# ATSAMHA1G16AB device description
Architecture: CORTEX-M0PLUS; Family: SAMH; Series: SAMHA1
Registers are 32-bit, read-write, reset 0x0 unless marked. A register's access mark holds for its fields unless they carry their own. Offsets are from the block's base; [hi:lo] are bit positions; lines under a group give offsets from that group; {n}, {i} and the like mark numbered series; 'fields as' and 'values as' point back to an identical list; <NAME> marks a mode.

## RTC — Real-Time Counter
Instances: RTC 0x40001400
Modes: MODE0 when RTC.MODE0.CTRL.MODE=0 (32-bit Counter with Single 32-bit Compare); MODE1 when RTC.MODE1.CTRL.MODE=1 (16-bit Counter with Two 16-bit Compares); MODE2 when RTC.MODE2.CTRL.MODE=2 (Clock/Calendar with Alarm)
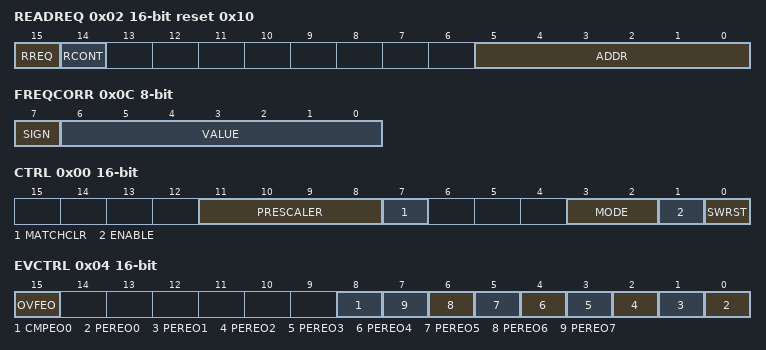
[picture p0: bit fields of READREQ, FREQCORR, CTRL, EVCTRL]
0x02 READREQ 16-bit reset 0x10 — Read Request
  [15] RREQ — Read Request
  [14] RCONT — Read Continuously
  [5:0] ADDR — Address
0x0A STATUS 8-bit
  [7] SYNCBUSY — Synchronization Busy
0x0B DBGCTRL 8-bit — Debug Control
  [0] DBGRUN — Run During Debug
0x0C FREQCORR 8-bit (WSYNC) — Frequency Correction
  [7] SIGN — Correction Sign
  [6:0] VALUE — Correction Value
0x00 CTRL <MODE0> 16-bit (WSYNC) — MODE0 Control
  [11:8] PRESCALER
    0=DIV1 (CLK_RTC_CNT = GCLK_RTC/1); 1=DIV2 (CLK_RTC_CNT = GCLK_RTC/2); 2=DIV4 (CLK_RTC_CNT = GCLK_RTC/4); 3=DIV8 (CLK_RTC_CNT = GCLK_RTC/8); 4=DIV16 (CLK_RTC_CNT = GCLK_RTC/16); 5=DIV32 (CLK_RTC_CNT = GCLK_RTC/32); 6=DIV64 (CLK_RTC_CNT = GCLK_RTC/64); 7=DIV128 (CLK_RTC_CNT = GCLK_RTC/128); 8=DIV256 (CLK_RTC_CNT = GCLK_RTC/256); 9=DIV512 (CLK_RTC_CNT = GCLK_RTC/512); 10=DIV1024 (CLK_RTC_CNT = GCLK_RTC/1024)
  [7] MATCHCLR — Clear on Match
  [3:2] MODE — Operating Mode
    0=COUNT32 (Mode 0: 32-bit Counter); 1=COUNT16 (Mode 1: 16-bit Counter); 2=CLOCK (Mode 2: Clock/Calendar)
  [1] ENABLE
  [0] SWRST — Software Reset
0x04 EVCTRL <MODE0> 16-bit — MODE0 Event Control
  [15] OVFEO — Overflow Event Output Enable
  [8] CMPEO0 — Compare 0 Event Output Enable
  [n] PEREO{n} (n=0..7) — Periodic Interval {n} Event Output Enable
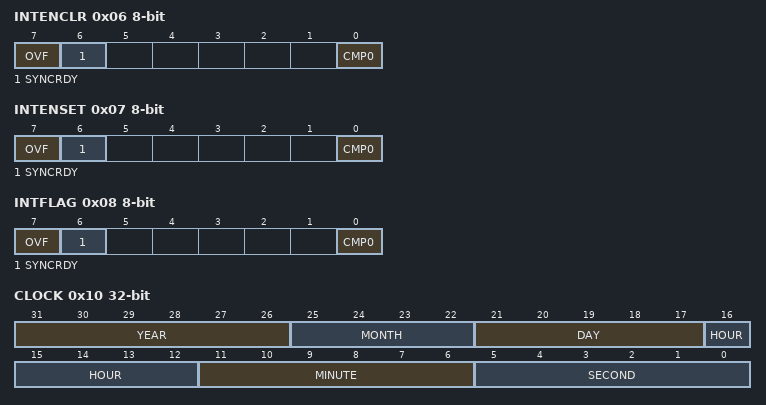
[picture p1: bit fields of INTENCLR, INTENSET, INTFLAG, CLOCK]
0x06 INTENCLR <MODE0> 8-bit (atomic clear) — MODE0 Interrupt Enable Clear
  [7] OVF — Overflow Interrupt Enable
  [6] SYNCRDY — Synchronization Ready Interrupt Enable
  [0] CMP0 — Compare 0 Interrupt Enable
0x07 INTENSET <MODE0> 8-bit (atomic set) — MODE0 Interrupt Enable Set
  fields as INTENCLR<MODE0>
0x08 INTFLAG <MODE0> 8-bit (atomic clear) — MODE0 Interrupt Flag Status and Clear
  [7] OVF — Overflow
  [6] SYNCRDY — Synchronization Ready
  [0] CMP0 — Compare 0
0x10 COUNT <MODE0> (RWSYNC) — MODE0 Counter Value
  [31:0] COUNT — Counter Value
0x18 COMP <MODE0> (WSYNC) — MODE0 Compare n Value
  [31:0] COMP — Compare Value
0x00 CTRL <MODE1> 16-bit (WSYNC) — MODE1 Control
  [11:8] PRESCALER
    values as CTRL<MODE0>.PRESCALER
  [3:2] MODE — Operating Mode
    values as CTRL<MODE0>.MODE
  [1] ENABLE
  [0] SWRST — Software Reset
0x04 EVCTRL <MODE1> 16-bit — MODE1 Event Control
  [15] OVFEO — Overflow Event Output Enable
  [9] CMPEO1 — Compare 1 Event Output Enable
  [8] CMPEO0 — Compare 0 Event Output Enable
  [n] PEREO{n} (n=0..7) — Periodic Interval {n} Event Output Enable
0x06 INTENCLR <MODE1> 8-bit (atomic clear) — MODE1 Interrupt Enable Clear
  [7] OVF — Overflow Interrupt Enable
  [6] SYNCRDY — Synchronization Ready Interrupt Enable
  [1] CMP1 — Compare 1 Interrupt Enable
  [0] CMP0 — Compare 0 Interrupt Enable
0x07 INTENSET <MODE1> 8-bit (atomic set) — MODE1 Interrupt Enable Set
  fields as INTENCLR<MODE1>
0x08 INTFLAG <MODE1> 8-bit (atomic clear) — MODE1 Interrupt Flag Status and Clear
  [7] OVF — Overflow
  [6] SYNCRDY — Synchronization Ready
  [1] CMP1 — Compare 1
  [0] CMP0 — Compare 0
0x10 COUNT <MODE1> 16-bit (RWSYNC) — MODE1 Counter Value
  [15:0] COUNT — Counter Value
0x14 PER <MODE1> 16-bit (WSYNC) — MODE1 Counter Period
  [15:0] PER — Counter Period
{0x18+2i} COMP[{i}] (i=0..1) <MODE1> 16-bit (WSYNC) — MODE1 Compare n Value
  [15:0] COMP — Compare Value
0x00 CTRL <MODE2> 16-bit (WSYNC) — MODE2 Control
  [11:8] PRESCALER
    values as CTRL<MODE0>.PRESCALER
  [7] MATCHCLR — Clear on Match
  [6] CLKREP — Clock Representation
  [3:2] MODE — Operating Mode
    values as CTRL<MODE0>.MODE
  [1] ENABLE
  [0] SWRST — Software Reset
0x04 EVCTRL <MODE2> 16-bit — MODE2 Event Control
  [15] OVFEO — Overflow Event Output Enable
  [8] ALARMEO0 — Alarm 0 Event Output Enable
  [n] PEREO{n} (n=0..7) — Periodic Interval {n} Event Output Enable
0x06 INTENCLR <MODE2> 8-bit (atomic clear) — MODE2 Interrupt Enable Clear
  [7] OVF — Overflow Interrupt Enable
  [6] SYNCRDY — Synchronization Ready Interrupt Enable
  [0] ALARM0 — Alarm 0 Interrupt Enable
0x07 INTENSET <MODE2> 8-bit (atomic set) — MODE2 Interrupt Enable Set
  fields as INTENCLR<MODE2>
0x08 INTFLAG <MODE2> 8-bit (atomic clear) — MODE2 Interrupt Flag Status and Clear
  [7] OVF — Overflow
  [6] SYNCRDY — Synchronization Ready
  [0] ALARM0
0x10 CLOCK <MODE2> (RWSYNC) — MODE2 Clock Value
  [31:26] YEAR
  [25:22] MONTH
  [21:17] DAY
  [16:12] HOUR
    0=AM (AM when CLKREP in 12-hour); 16=PM (PM when CLKREP in 12-hour)
  [11:6] MINUTE
  [5:0] SECOND
0x18 MODE2_ALARM <MODE2> group
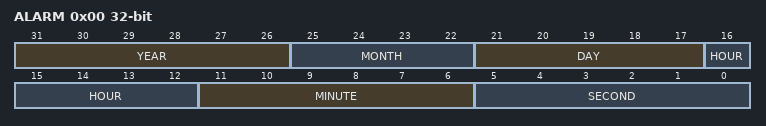
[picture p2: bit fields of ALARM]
  0x00 ALARM <MODE2> (WSYNC) — MODE2_ALARM Alarm n Value
    [31:26] YEAR
    [25:22] MONTH
    [21:17] DAY
    [16:12] HOUR
      0=AM (Morning hour); 16=PM (Afternoon hour)
    [11:6] MINUTE
    [5:0] SECOND
  0x04 MASK <MODE2> 8-bit (WSYNC) — MODE2_ALARM Alarm n Mask
    [2:0] SEL — Alarm Mask Selection
      0=OFF (Alarm Disabled); 1=SS (Match seconds only); 2=MMSS (Match seconds and minutes only); 3=HHMMSS (Match seconds, minutes, and hours only); 4=DDHHMMSS (Match seconds, minutes, hours, and days only); 5=MMDDHHMMSS (Match seconds, minutes, hours, days, and months only); 6=YYMMDDHHMMSS (Match seconds, minutes, hours, days, months, and years)

## Notices in the file
Copyright (c) 2018 Microchip Technology Inc.
SPDX-License-Identifier: Apache-2.0
Licensed under the Apache License, Version 2.0 (the "License");
you may not use this file except in compliance with the License.
You may obtain a copy of the License at
http://www.apache.org/licenses/LICENSE-2.0
Unless required by applicable law or agreed to in writing, software
distributed under the License is distributed on an "AS IS" BASIS,
WITHOUT WARRANTIES OR CONDITIONS OF ANY KIND, either express or implied.
See the License for the specific language governing permissions and
limitations under the License.
